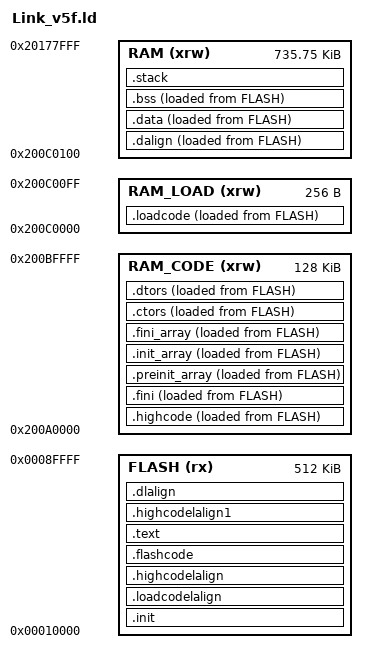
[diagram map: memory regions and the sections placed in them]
ENTRY( _start )

__stack_size = 4096;

PROVIDE( _stack_size = __stack_size );


MEMORY
{
	/* 896KB total: ITCM(128K) + DTCM(256K) + SRAM(512K)
	   V3F occupies last 32K of SRAM (0x20178000-0x20180000)
	   注意：ITCM 物理上只有 128K，DTCM 不能取指，RAM_CODE 严禁超过 128K；
	   超出部分一旦执行即崩溃（历史上"删 Game 才能跑"的根因）。
	   代码放不下的低热度模块应放入 .flashcode 段（FLASH XIP 执行）。 */
	FLASH (rx) : ORIGIN = 0x00010000, LENGTH = 512K                    /* zero_wait flash, XIP for .flashcode + load source */
	RAM_CODE (xrw) : ORIGIN = 0x200A0000, LENGTH = 128K                /* ITCM 128K for V5F code execution (physical limit!) */
	RAM (xrw) : ORIGIN = (0x200C0000+256), LENGTH = (0x20178000 - 0x200C0000 - 256) /* DTCM(256K)+SRAM for .data/.bss, V5F up to V3F boundary */
	RAM_LOAD (xrw) : ORIGIN = 0x200C0000, LENGTH = 256                /* RAM for .load section */
}

SECTIONS
{
	.init :
	{
		_sinit = .;
		. = ALIGN(4);
		KEEP(*(SORT_NONE(.init)))
		. = ALIGN(4);
		_einit = .;
	} >FLASH AT>FLASH

    .loadcodelalign : 
    {       
        . = ALIGN(4);
        PROVIDE(_loadcode_lma = .); 
    } >FLASH AT>FLASH 

	.loadcode :
	{
		. = ALIGN(4);
        PROVIDE(_loadcode_vma_start = .);
		*(.load);
		. = ALIGN(4); 
		PROVIDE(_loadcode_vma_end = .);
	}>RAM_LOAD AT>FLASH

    .highcodelalign : 
    {       
        . = ALIGN(4);
        PROVIDE(_highcode_lma = .); 
    } >FLASH AT>FLASH 
    
    .highcode : 
    {
        . = ALIGN(4);
        PROVIDE(_highcode_vma_start = .);
        *(.vector);
		KEEP(*(SORT_NONE(.vector_handler)))
		*(.text)
		*(EXCLUDE_FILE (*/app_usb.o */app_power.o */app_bt.o */app_nfc.o */app_fingerprint.o */app_subdisplay.o */app_irrange.o) .text.*)
		*(.glue_7)
		*(.glue_7t)
		*(.gnu.linkonce.t.*)
		. = ALIGN(4); 
        PROVIDE(_highcode_vma_end = .);
    } >RAM_CODE AT>FLASH

	/* 低热度代码直接在 FLASH 执行（XIP），不占用物理 ITCM 128K。
	 * 无动画/低频交互的 APP（USB、Power、BT、NFC、指纹、副屏、红外）放这里；
	 * 游戏等帧率敏感模块必须留在 .highcode(ITCM)（Flash XIP 有等待周期，
	 * 游戏动画会明显变慢，血泪教训）。
	 * ISR、渲染、协议解析、驱动等热路径必须留在 .highcode(ITCM)。 */
	.flashcode :
	{
		. = ALIGN(4);
		*/app_usb.o(.text.*)
		*/app_power.o(.text.*)
		*/app_bt.o(.text.*)
		*/app_nfc.o(.text.*)
		*/app_fingerprint.o(.text.*)
		*/app_subdisplay.o(.text.*)
		*/app_irrange.o(.text.*)
		. = ALIGN(4);
	} >FLASH AT>FLASH

	.text :
	{
		. = ALIGN(4);
		KEEP(*(SORT_NONE(.handle_reset)))
		. = ALIGN(4);
	} >FLASH AT>FLASH

    .highcodelalign1 : 
    {       
        . = ALIGN(4);
        PROVIDE(_highcode_lma1 = .); 
    } >FLASH AT>FLASH 

	.fini :
	{
	    . = ALIGN(4);
        PROVIDE(_highcode_vma_start1 = .);
		KEEP(*(SORT_NONE(.fini)))
		. = ALIGN(4);
	} >RAM_CODE AT>FLASH

	PROVIDE( _etext = . );
	PROVIDE( _eitcm = . );	

	.preinit_array  :
	{
	  PROVIDE_HIDDEN (__preinit_array_start = .);
	  KEEP (*(.preinit_array))
	  PROVIDE_HIDDEN (__preinit_array_end = .);
	} >RAM_CODE AT>FLASH 
	
	.init_array     :
	{
	  PROVIDE_HIDDEN (__init_array_start = .);
	  KEEP (*(SORT_BY_INIT_PRIORITY(.init_array.*) SORT_BY_INIT_PRIORITY(.ctors.*)))
	  KEEP (*(.init_array EXCLUDE_FILE (*crtbegin.o *crtbegin?.o *crtend.o *crtend?.o ) .ctors))
	  PROVIDE_HIDDEN (__init_array_end = .);
	} >RAM_CODE AT>FLASH 
	
	.fini_array     :
	{
	  PROVIDE_HIDDEN (__fini_array_start = .);
	  KEEP (*(SORT_BY_INIT_PRIORITY(.fini_array.*) SORT_BY_INIT_PRIORITY(.dtors.*)))
	  KEEP (*(.fini_array EXCLUDE_FILE (*crtbegin.o *crtbegin?.o *crtend.o *crtend?.o ) .dtors))
	  PROVIDE_HIDDEN (__fini_array_end = .);
	} >RAM_CODE AT>FLASH 
	
	.ctors          :
	{
	  /* gcc uses crtbegin.o to find the start of
	     the constructors, so we make sure it is
	     first.  Because this is a wildcard, it
	     doesn't matter if the user does not
	     actually link against crtbegin.o; the
	     linker won't look for a file to match a
	     wildcard.  The wildcard also means that it
	     doesn't matter which directory crtbegin.o
	     is in.  */
	  KEEP (*crtbegin.o(.ctors))
	  KEEP (*crtbegin?.o(.ctors))
	  /* We don't want to include the .ctor section from
	     the crtend.o file until after the sorted ctors.
	     The .ctor section from the crtend file contains the
	     end of ctors marker and it must be last */
	  KEEP (*(EXCLUDE_FILE (*crtend.o *crtend?.o ) .ctors))
	  KEEP (*(SORT(.ctors.*)))
	  KEEP (*(.ctors))
	} >RAM_CODE AT>FLASH 
	
	.dtors          :
	{
	  KEEP (*crtbegin.o(.dtors))
	  KEEP (*crtbegin?.o(.dtors))
	  KEEP (*(EXCLUDE_FILE (*crtend.o *crtend?.o ) .dtors))
	  KEEP (*(SORT(.dtors.*)))
	  KEEP (*(.dtors))
	  . = ALIGN(4); 
      PROVIDE(_highcode_vma_end1 = .);
	} >RAM_CODE AT>FLASH 

	.dalign :
	{
		. = ALIGN(4);
		PROVIDE(_data_vma = .);
	} >RAM AT>FLASH	

	.dlalign :
	{
		. = ALIGN(4); 
		PROVIDE(_data_lma = .);
	} >FLASH AT>FLASH

	.data :
	{
		. = ALIGN(4);
    	*(.gnu.linkonce.r.*)
    	*(.data .data.*)
    	*(.gnu.linkonce.d.*)
		. = ALIGN(8);
    	PROVIDE( __global_pointer$ = . + 0x800 );
    	*(.sdata .sdata.*)
		*(.sdata2.*)
    	*(.gnu.linkonce.s.*)
    	. = ALIGN(4);
    	*(.rodata)
    	*(.rodata*)
    	. = ALIGN(8);
    	*(.srodata.cst16)
    	*(.srodata.cst8)
    	*(.srodata.cst4)
    	*(.srodata.cst2)
    	*(.srodata .srodata.*)
    	. = ALIGN(4);
		PROVIDE( _edata = .);
	} >RAM AT>FLASH

	.bss :
	{
		. = ALIGN(4);
		PROVIDE( _sbss = .);
  	    *(.sbss*)
        *(.gnu.linkonce.sb.*)
		*(.bss*)
     	*(.gnu.linkonce.b.*)		
		*(COMMON*)
		. = ALIGN(4);
		PROVIDE( _ebss = .);
	} >RAM AT>FLASH

	PROVIDE( _end = _ebss);
	PROVIDE( end = . );

    .stack ORIGIN(RAM) + LENGTH(RAM) - __stack_size :
    {
        PROVIDE( _heap_end = . );    
        . = ALIGN(4);
        PROVIDE(_susrstack = . );
        . = . + __stack_size;
        PROVIDE( _eusrstack = .);
    } >RAM 

}



